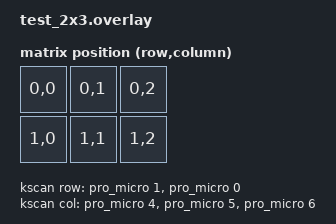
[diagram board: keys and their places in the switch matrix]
// This file was generated from a template. Edit it to match your keyboard.
// See https://zmk.dev/docs/development/hardware-integration/new-shield for more
// instructions.

#include <dt-bindings/zmk/matrix_transform.h>

#include "test_2x3-layouts.dtsi"

/ {
    chosen {
        zmk,physical-layout = &default_layout;
    };

    kscan: kscan {
        // If the hardware does not use a switch matrix, change this to the
        // appropriate driver and update the properties below to match.
        // See https://zmk.dev/docs/config/kscan for supported key scan drivers.
        compatible = "zmk,kscan-gpio-matrix";
        // Set this to "col2row" or "row2col" to match the hardware. If using
        // "row2col", change the col-gpios to (GPIO_ACTIVE_HIGH | GPIO_PULL_DOWN)
        // and the row-gpios to GPIO_ACTIVE_HIGH.
        diode-direction = "col2row";
        wakeup-source;

        // Replace these comments with the GPIO pins in the matrix.
        // See https://zmk.dev/docs/development/hardware-integration/new-shield#shield-overlays
        col-gpios
            = <&pro_micro 4 GPIO_ACTIVE_HIGH> // P0.17
            , <&pro_micro 5 GPIO_ACTIVE_HIGH> // P0.20
            , <&pro_micro 6 GPIO_ACTIVE_HIGH> // P0.22
            ;

        row-gpios
            = <&pro_micro 1 (GPIO_ACTIVE_HIGH | GPIO_PULL_DOWN)> // P.06
            , <&pro_micro 0 (GPIO_ACTIVE_HIGH | GPIO_PULL_DOWN)> // P.08
            ;
    };

    default_transform: default_transform {
        // See https://zmk.dev/docs/development/hardware-integration/new-shield#matrix-transform
        // for how to configure this
        compatible = "zmk,matrix-transform";
        columns = <3>;
        rows = <2>;

        map = <
            RC(0, 0) RC(0, 1) RC(0, 2)
            RC(1, 0) RC(1, 1) RC(1, 2)
        >;
    };
};
